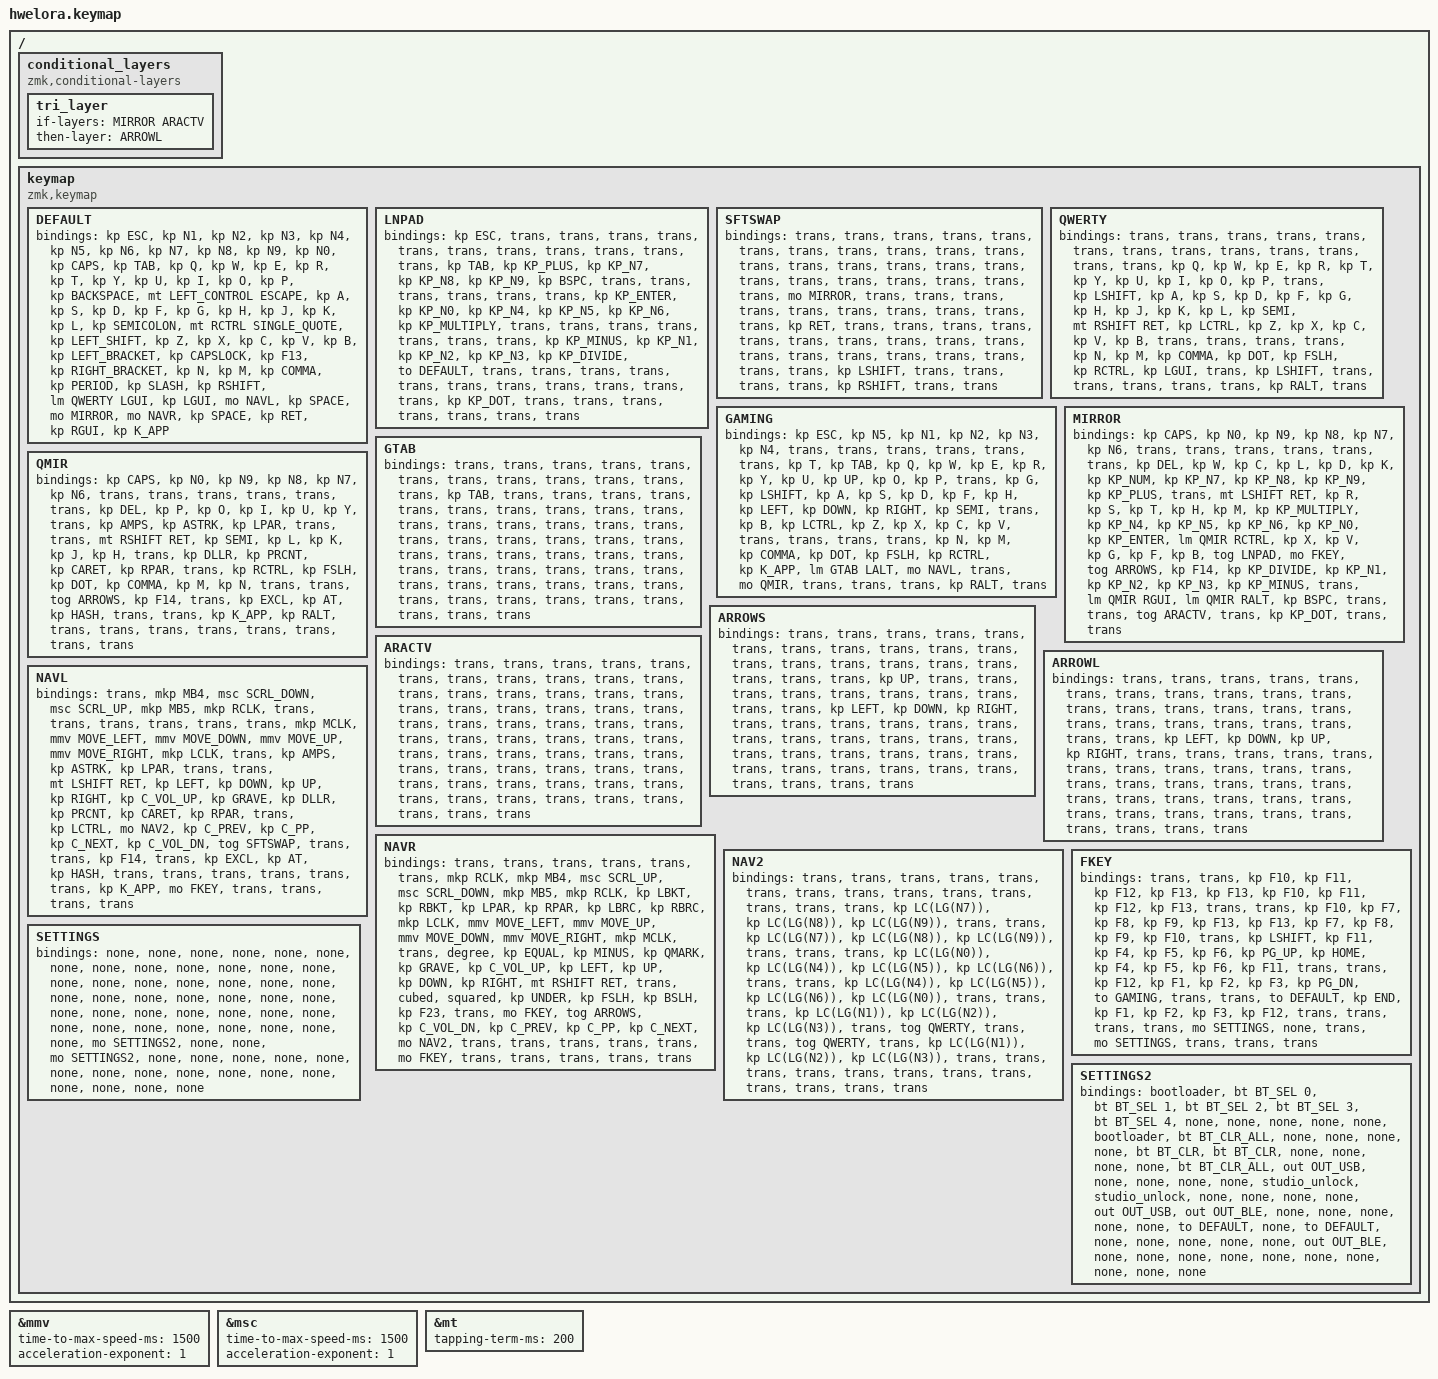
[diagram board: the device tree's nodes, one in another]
#define ZMK_POINTING_DEFAULT_MOVE_VAL 2000
#define ZMK_POINTING_DEFAULT_SCRL_VAL 200

#include <behaviors.dtsi>
#include <dt-bindings/zmk/bt.h>
#include <dt-bindings/zmk/keys.h>
#include <dt-bindings/zmk/outputs.h>
#include <dt-bindings/zmk/pointing.h>

&mmv {
    time-to-max-speed-ms = <1500>;
    acceleration-exponent = <1>;
};

&msc {
    time-to-max-speed-ms = <1500>;
    acceleration-exponent = <1>;
};

#define DEFAULT     0
#define LNPAD	      1
#define SFTSWAP     2
#define QWERTY      3
#define GAMING      4
#define MIRROR      5
#define QMIR        6
#define GTAB        7
#define ARROWS      8
#define ARACTV      9
#define ARROWL      10
#define NAVL        11
#define NAVR        12
#define NAV2        13
#define FKEY        14
#define SETTINGS    15
#define SETTINGS2   16

/ {
    conditional_layers {
        compatible = "zmk,conditional-layers";

        tri_layer {
            if-layers = <MIRROR ARACTV>;
            then-layer = <ARROWL>;
        };
    };
};

/ {
};

&mt { tapping-term-ms = <200>; };

/ {
    keymap {
        compatible = "zmk,keymap";

        DEFAULT {
            bindings = <
&kp ESC                  &kp N1  &kp N2  &kp N3           &kp N4    &kp N5                                                                   &kp N6   &kp N7    &kp N8     &kp N9      &kp N0         &kp CAPS
&kp TAB                  &kp Q   &kp W   &kp E            &kp R     &kp T                                                                    &kp Y    &kp U     &kp I      &kp O       &kp P          &kp BACKSPACE
&mt LEFT_CONTROL ESCAPE  &kp A   &kp S   &kp D            &kp F     &kp G                                                                    &kp H    &kp J     &kp K      &kp L       &kp SEMICOLON  &mt RCTRL SINGLE_QUOTE
&kp LEFT_SHIFT           &kp Z   &kp X   &kp C            &kp V     &kp B     &kp LEFT_BRACKET  &kp CAPSLOCK    &kp F13   &kp RIGHT_BRACKET  &kp N    &kp M     &kp COMMA  &kp PERIOD  &kp SLASH      &kp RSHIFT
                                         &lm QWERTY LGUI  &kp LGUI  &mo NAVL  &kp SPACE         &mo MIRROR      &mo NAVR  &kp SPACE          &kp RET  &kp RGUI  &kp K_APP
            >;
        };

        LNPAD {
            bindings = <
&kp ESC       &trans        &trans     &trans     &trans     &trans                                                  &trans  &trans  &trans  &trans  &trans  &trans
&kp TAB       &kp KP_PLUS   &kp KP_N7  &kp KP_N8  &kp KP_N9  &kp BSPC                                                &trans  &trans  &trans  &trans  &trans  &trans
&kp KP_ENTER  &kp KP_N0     &kp KP_N4  &kp KP_N5  &kp KP_N6  &kp KP_MULTIPLY                                         &trans  &trans  &trans  &trans  &trans  &trans
&trans        &kp KP_MINUS  &kp KP_N1  &kp KP_N2  &kp KP_N3  &kp KP_DIVIDE    &to DEFAULT  &trans    &trans  &trans  &trans  &trans  &trans  &trans  &trans  &trans
                                       &trans     &trans     &kp KP_DOT       &trans       &trans    &trans  &trans  &trans  &trans  &trans
            >;
        };

        SFTSWAP {
            bindings = <
&trans      &trans  &trans  &trans  &trans  &trans                                        &trans      &trans  &trans  &trans  &trans  &trans
&trans      &trans  &trans  &trans  &trans  &trans                                        &trans      &trans  &trans  &trans  &trans  &trans
&mo MIRROR  &trans  &trans  &trans  &trans  &trans                                        &trans      &trans  &trans  &trans  &trans  &kp RET
&trans      &trans  &trans  &trans  &trans  &trans      &trans  &trans    &trans  &trans  &trans      &trans  &trans  &trans  &trans  &trans
                            &trans  &trans  &kp LSHIFT  &trans  &trans    &trans  &trans  &kp RSHIFT  &trans  &trans
            >;
        };

        QWERTY {
            bindings = <
&trans      &trans  &trans  &trans    &trans  &trans                                        &trans  &trans    &trans     &trans   &trans    &trans
&trans      &kp Q   &kp W   &kp E     &kp R   &kp T                                         &kp Y   &kp U     &kp I      &kp O    &kp P     &trans
&kp LSHIFT  &kp A   &kp S   &kp D     &kp F   &kp G                                         &kp H   &kp J     &kp K      &kp L    &kp SEMI  &mt RSHIFT RET
&kp LCTRL   &kp Z   &kp X   &kp C     &kp V   &kp B       &trans  &trans    &trans  &trans  &kp N   &kp M     &kp COMMA  &kp DOT  &kp FSLH  &kp RCTRL
                            &kp LGUI  &trans  &kp LSHIFT  &trans  &trans    &trans  &trans  &trans  &kp RALT  &trans
            >;
        };

        GAMING {
            bindings = <
&kp ESC  &kp N5      &kp N1  &kp N2     &kp N3         &kp N4                                        &trans  &trans    &trans     &trans     &trans    &trans
&kp T    &kp TAB     &kp Q   &kp W      &kp E          &kp R                                         &kp Y   &kp U     &kp UP     &kp O      &kp P     &trans
&kp G    &kp LSHIFT  &kp A   &kp S      &kp D          &kp F                                         &kp H   &kp LEFT  &kp DOWN   &kp RIGHT  &kp SEMI  &trans
&kp B    &kp LCTRL   &kp Z   &kp X      &kp C          &kp V     &trans  &trans      &trans  &trans  &kp N   &kp M     &kp COMMA  &kp DOT    &kp FSLH  &kp RCTRL
                             &kp K_APP  &lm GTAB LALT  &mo NAVL  &trans  &mo QMIR    &trans  &trans  &trans  &kp RALT  &trans
            >;
        };

        MIRROR {
            bindings = <
&kp CAPS        &kp N0  &kp N9  &kp N8         &kp N7         &kp N6                                                  &trans           &trans     &trans     &trans     &trans        &trans
&kp DEL         &kp W   &kp C   &kp L          &kp D          &kp K                                                   &kp KP_NUM       &kp KP_N7  &kp KP_N8  &kp KP_N9  &kp KP_PLUS   &trans
&mt LSHIFT RET  &kp R   &kp S   &kp T          &kp H          &kp M                                                   &kp KP_MULTIPLY  &kp KP_N4  &kp KP_N5  &kp KP_N6  &kp KP_N0     &kp KP_ENTER
&lm QMIR RCTRL  &kp X   &kp V   &kp G          &kp F          &kp B     &tog LNPAD  &mo FKEY    &tog ARROWS  &kp F14  &kp KP_DIVIDE    &kp KP_N1  &kp KP_N2  &kp KP_N3  &kp KP_MINUS  &trans
                                &lm QMIR RGUI  &lm QMIR RALT  &kp BSPC  &trans      &trans      &tog ARACTV  &trans   &kp KP_DOT       &trans     &trans
            >;
        };

        QMIR {
            bindings = <
&kp CAPS        &kp N0    &kp N9   &kp N8     &kp N7    &kp N6                                          &trans  &trans    &trans     &trans     &trans    &trans
&kp DEL         &kp P     &kp O    &kp I      &kp U     &kp Y                                           &trans  &kp AMPS  &kp ASTRK  &kp LPAR   &trans    &trans
&mt RSHIFT RET  &kp SEMI  &kp L    &kp K      &kp J     &kp H                                           &trans  &kp DLLR  &kp PRCNT  &kp CARET  &kp RPAR  &trans
&kp RCTRL       &kp FSLH  &kp DOT  &kp COMMA  &kp M     &kp N   &trans  &trans    &tog ARROWS  &kp F14  &trans  &kp EXCL  &kp AT     &kp HASH   &trans    &trans
                                   &kp K_APP  &kp RALT  &trans  &trans  &trans    &trans       &trans   &trans  &trans    &trans
            >;
        };

        GTAB {
            bindings = <
&trans   &trans  &trans  &trans  &trans  &trans                                    &trans  &trans  &trans  &trans  &trans  &trans
&kp TAB  &trans  &trans  &trans  &trans  &trans                                    &trans  &trans  &trans  &trans  &trans  &trans
&trans   &trans  &trans  &trans  &trans  &trans                                    &trans  &trans  &trans  &trans  &trans  &trans
&trans   &trans  &trans  &trans  &trans  &trans  &trans  &trans    &trans  &trans  &trans  &trans  &trans  &trans  &trans  &trans
                         &trans  &trans  &trans  &trans  &trans    &trans  &trans  &trans  &trans  &trans
            >;
        };

        ARROWS {
            bindings = <
&trans  &trans  &trans  &trans  &trans  &trans                                    &trans  &trans    &trans    &trans     &trans  &trans
&trans  &trans  &trans  &trans  &trans  &trans                                    &trans  &trans    &kp UP    &trans     &trans  &trans
&trans  &trans  &trans  &trans  &trans  &trans                                    &trans  &kp LEFT  &kp DOWN  &kp RIGHT  &trans  &trans
&trans  &trans  &trans  &trans  &trans  &trans  &trans  &trans    &trans  &trans  &trans  &trans    &trans    &trans     &trans  &trans
                        &trans  &trans  &trans  &trans  &trans    &trans  &trans  &trans  &trans    &trans
            >;
        };

        ARACTV {
            bindings = <
&trans  &trans  &trans  &trans  &trans  &trans                                    &trans  &trans  &trans  &trans  &trans  &trans
&trans  &trans  &trans  &trans  &trans  &trans                                    &trans  &trans  &trans  &trans  &trans  &trans
&trans  &trans  &trans  &trans  &trans  &trans                                    &trans  &trans  &trans  &trans  &trans  &trans
&trans  &trans  &trans  &trans  &trans  &trans  &trans  &trans    &trans  &trans  &trans  &trans  &trans  &trans  &trans  &trans
                        &trans  &trans  &trans  &trans  &trans    &trans  &trans  &trans  &trans  &trans
            >;
        };

        ARROWL {
            bindings = <
&trans  &trans    &trans    &trans  &trans     &trans                                    &trans  &trans  &trans  &trans  &trans  &trans
&trans  &trans    &trans    &trans  &trans     &trans                                    &trans  &trans  &trans  &trans  &trans  &trans
&trans  &kp LEFT  &kp DOWN  &kp UP  &kp RIGHT  &trans                                    &trans  &trans  &trans  &trans  &trans  &trans
&trans  &trans    &trans    &trans  &trans     &trans  &trans  &trans    &trans  &trans  &trans  &trans  &trans  &trans  &trans  &trans
                            &trans  &trans     &trans  &trans  &trans    &trans  &trans  &trans  &trans  &trans
            >;
        };

        NAVL {
            bindings = <
&trans          &mkp MB4        &msc SCRL_DOWN  &msc SCRL_UP  &mkp MB5         &mkp RCLK                                                   &trans     &trans    &trans     &trans     &trans    &trans
&mkp MCLK       &mmv MOVE_LEFT  &mmv MOVE_DOWN  &mmv MOVE_UP  &mmv MOVE_RIGHT  &mkp LCLK                                                   &trans     &kp AMPS  &kp ASTRK  &kp LPAR   &trans    &trans
&mt LSHIFT RET  &kp LEFT        &kp DOWN        &kp UP        &kp RIGHT        &kp C_VOL_UP                                                &kp GRAVE  &kp DLLR  &kp PRCNT  &kp CARET  &kp RPAR  &trans
&kp LCTRL       &mo NAV2        &kp C_PREV      &kp C_PP      &kp C_NEXT       &kp C_VOL_DN  &tog SFTSWAP  &trans       &trans    &kp F14  &trans     &kp EXCL  &kp AT     &kp HASH   &trans    &trans
                                                &trans        &trans           &trans        &trans        &kp K_APP    &mo FKEY  &trans   &trans     &trans    &trans
            >;
        };

        NAVR {
            bindings = <
&trans    &trans    &trans     &trans     &trans     &trans                                                 &mkp RCLK     &mkp MB4        &msc SCRL_UP  &msc SCRL_DOWN  &mkp MB5         &mkp RCLK
&kp LBKT  &kp RBKT  &kp LPAR   &kp RPAR   &kp LBRC   &kp RBRC                                               &mkp LCLK     &mmv MOVE_LEFT  &mmv MOVE_UP  &mmv MOVE_DOWN  &mmv MOVE_RIGHT  &mkp MCLK
&trans    &degree   &kp EQUAL  &kp MINUS  &kp QMARK  &kp GRAVE                                              &kp C_VOL_UP  &kp LEFT        &kp UP        &kp DOWN        &kp RIGHT        &mt RSHIFT RET
&trans    &cubed    &squared   &kp UNDER  &kp FSLH   &kp BSLH   &kp F23  &trans      &mo FKEY  &tog ARROWS  &kp C_VOL_DN  &kp C_PREV      &kp C_PP      &kp C_NEXT      &mo NAV2         &trans
                               &trans     &trans     &trans     &trans   &mo FKEY    &trans    &trans       &trans        &trans          &trans
            >;
        };

        NAV2 {
            bindings = <
&trans  &trans          &trans          &trans          &trans          &trans                                              &trans  &trans          &trans          &trans          &trans          &trans
&trans  &trans          &kp LC(LG(N7))  &kp LC(LG(N8))  &kp LC(LG(N9))  &trans                                              &trans  &kp LC(LG(N7))  &kp LC(LG(N8))  &kp LC(LG(N9))  &trans          &trans
&trans  &kp LC(LG(N0))  &kp LC(LG(N4))  &kp LC(LG(N5))  &kp LC(LG(N6))  &trans                                              &trans  &kp LC(LG(N4))  &kp LC(LG(N5))  &kp LC(LG(N6))  &kp LC(LG(N0))  &trans
&trans  &trans          &kp LC(LG(N1))  &kp LC(LG(N2))  &kp LC(LG(N3))  &trans  &tog QWERTY  &trans    &trans  &tog QWERTY  &trans  &kp LC(LG(N1))  &kp LC(LG(N2))  &kp LC(LG(N3))  &trans          &trans
                                        &trans          &trans          &trans  &trans       &trans    &trans  &trans       &trans  &trans          &trans
            >;
        };

        FKEY {
            bindings = <
&trans      &trans   &kp F10  &kp F11  &kp F12  &kp F13                                                  &kp F13   &kp F10  &kp F11  &kp F12  &kp F13  &trans
&trans      &kp F10  &kp F7   &kp F8   &kp F9   &kp F13                                                  &kp F13   &kp F7   &kp F8   &kp F9   &kp F10  &trans
&kp LSHIFT  &kp F11  &kp F4   &kp F5   &kp F6   &kp PG_UP                                                &kp HOME  &kp F4   &kp F5   &kp F6   &kp F11  &trans
&trans      &kp F12  &kp F1   &kp F2   &kp F3   &kp PG_DN  &to GAMING    &trans    &trans  &to DEFAULT   &kp END   &kp F1   &kp F2   &kp F3   &kp F12  &trans
                              &trans   &trans   &trans     &mo SETTINGS  &none     &trans  &mo SETTINGS  &trans    &trans   &trans
            >;
        };

        SETTINGS {
            bindings = <
&none  &none  &none  &none  &none  &none                                                &none  &none  &none  &none  &none  &none
&none  &none  &none  &none  &none  &none                                                &none  &none  &none  &none  &none  &none
&none  &none  &none  &none  &none  &none                                                &none  &none  &none  &none  &none  &none
&none  &none  &none  &none  &none  &none  &mo SETTINGS2  &none    &none  &mo SETTINGS2  &none  &none  &none  &none  &none  &none
                     &none  &none  &none  &none          &none    &none  &none          &none  &none  &none
            >;
        };

        SETTINGS2 {
            bindings = <
&bootloader     &bt BT_SEL 0  &bt BT_SEL 1  &bt BT_SEL 2  &bt BT_SEL 3  &bt BT_SEL 4                                              &none           &none  &none  &none  &none         &bootloader
&bt BT_CLR_ALL  &none         &none         &none         &none         &bt BT_CLR                                                &bt BT_CLR      &none  &none  &none  &none         &bt BT_CLR_ALL
&out OUT_USB    &none         &none         &none         &none         &studio_unlock                                            &studio_unlock  &none  &none  &none  &none         &out OUT_USB
&out OUT_BLE    &none         &none         &none         &none         &none           &to DEFAULT  &none    &to DEFAULT  &none  &none           &none  &none  &none  &out OUT_BLE  &none
                                            &none         &none         &none           &none        &none    &none        &none  &none           &none
            >;
        };
    };
};
